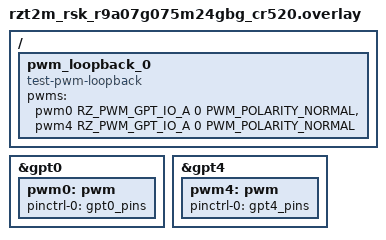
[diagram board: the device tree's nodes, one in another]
/*
 * Copyright (c) 2025 Renesas Electronics Corporation
 *
 * SPDX-License-Identifier: Apache-2.0
 */

#include <zephyr/dt-bindings/pwm/pwm.h>
#include <zephyr/dt-bindings/pwm/renesas_rz_pwm.h>

/ {
	pwm_loopback_0 {
		compatible = "test-pwm-loopback";
		pwms = <&pwm0 RZ_PWM_GPT_IO_A 0 PWM_POLARITY_NORMAL>,
		       <&pwm4 RZ_PWM_GPT_IO_A 0 PWM_POLARITY_NORMAL>;
	};
};

&gpt0 {
	status = "okay";

	pwm0: pwm {
		status = "okay";
		pinctrl-0 = <&gpt0_pins>;
		pinctrl-names = "default";
	};
};

&gpt4 {
	status = "okay";

	pwm4: pwm {
		status = "okay";
		pinctrl-0 = <&gpt4_pins>;
		pinctrl-names = "default";
	};
};
